VERSION ""

NS_ :

BS_:

BU_:

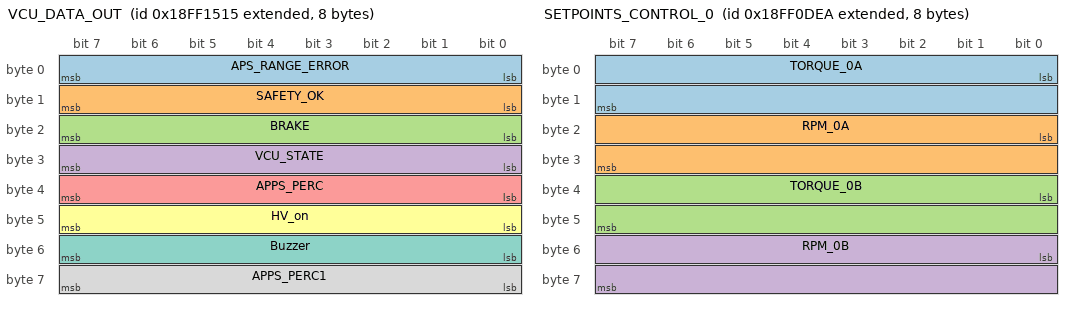
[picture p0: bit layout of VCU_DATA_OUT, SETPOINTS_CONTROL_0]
BO_ 2566853909 VCU_DATA_OUT: 8 Vector__XXX
 SG_ APS_RANGE_ERROR : 0|8@1+ (1,0) [0|1] "" Vector__XXX
 SG_ SAFETY_OK : 8|8@1+ (1,0) [0|1] "" Vector__XXX
 SG_ BRAKE : 16|8@1+ (1,0) [0|1] "" Vector__XXX
 SG_ VCU_STATE : 24|8@1+ (1,0) [0|4] "" Vector__XXX
 SG_ APPS_PERC : 32|8@1+ (1,0) [0|1] "" Vector__XXX
 SG_ HV_on : 40|8@1+ (1,0) [0|1] "" Vector__XXX
 SG_ Buzzer : 48|8@1+ (1,0) [0|30] "" Vector__XXX
 SG_ APPS_PERC1 : 56|8@1+ (1,0) [0|1] "" Vector__XXX

BO_ 2566852074 SETPOINTS_CONTROL_0: 8 Vector__XXX
 SG_ TORQUE_0A M : 0|16@1- (1,0) [-32768|32767] "Nm" Vector__XXX
 SG_ RPM_0A : 16|16@1- (1,0) [-32768|32767] "RPM" Vector__XXX
 SG_ TORQUE_0B : 32|16@1- (1,0) [-32768|32767] "Nm" Vector__XXX
 SG_ RPM_0B : 48|16@1- (1,0) [-32768|32767] "RPM" Vector__XXX

BO_ 3221225472 VECTOR__INDEPENDENT_SIG_MSG: 0 Vector__XXX
 SG_ RPM_0A : 23|8@0- (1,0) [0|0] "" Vector__XXX
 SG_ TORQUE_0A : 7|8@0- (1,0) [0|0] "Nm" Vector__XXX

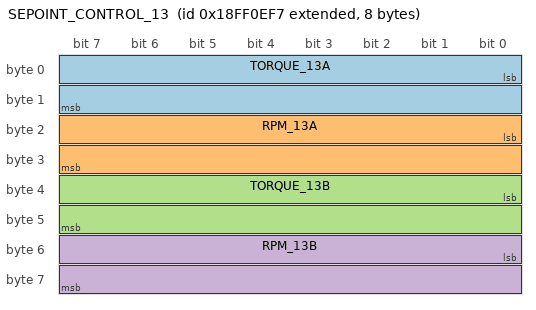
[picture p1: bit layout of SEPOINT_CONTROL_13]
BO_ 2566852343 SEPOINT_CONTROL_13: 8 Vector__XXX
 SG_ TORQUE_13A : 0|16@1- (1,0) [-32768|32767] "Nm" Vector__XXX
 SG_ RPM_13A : 16|16@1- (1,0) [-32768|32767] "RPM" Vector__XXX
 SG_ TORQUE_13B : 32|16@1- (1,0) [-32768|32767] "Nm" Vector__XXX
 SG_ RPM_13B : 48|16@1- (1,0) [-32768|32767] "RPM" Vector__XXX

VAL_ 2566853909 APS_RANGE_ERROR 1 "ERROR" 0 "OK" ;
VAL_ 2566853909 SAFETY_OK 1 "ERROR" 0 "OK" ;
VAL_ 2566853909 BRAKE 1 "BRAKE" 0 "NO BRAKE" ;
VAL_ 2566853909 VCU_STATE 0 "INICIAL" 1 "PRE CHARGE" 2 "BUZZER" 3 "OPERANDO" 4 "ERROR" ;
VAL_ 2566853909 APPS_PERC 0 "NR2D" 1 "R2D" ;
VAL_ 2566853909 HV_on 0 "HV_OFF" 1 "HV_ON" ;
